AUTOSAR XML (schema 4-2-1)
package /ComponentTypes
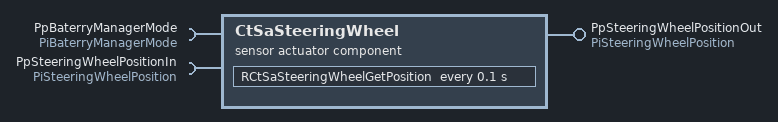
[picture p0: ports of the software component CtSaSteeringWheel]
  sensor actuator sw component type CtSaSteeringWheel
    provide port PpSteeringWheelPositionOut: nonqueued-sender-com-spec{data-element=DeSteeringWheelPosition, init-value=0}, provided-interface=PiSteeringWheelPosition
    require port PpBaterryManagerMode: mode-switch-receiver-com-spec{enhanced-mode-api=false, supports-asynchronous-mode-switch=false}, required-interface=PiBaterryManagerMode
    require port PpSteeringWheelPositionIn: nonqueued-receiver-com-spec{data-element=DeSteeringWheelPosition, filter=data-filter-type=ALWAYS, init-value=constant-reference=CSteeringWheelInitPosition}, required-interface=PiSteeringWheelPosition
    behavior CtSaSteeringWheel_InternalBehavior
      timing event TMT_RCtSaSteeringWheelGetPosition: disabled-mode=PpBaterryManagerMode.Mode.BATTERY_LOW, start-on-event=RCtSaSteeringWheelGetPosition, period=0.1
      runnable RCtSaSteeringWheelGetPosition
        data-receive-point-by-arguments:
          access REC_PpSteeringWheelPosition_DeSteeringWheelPosition: accessed-variable=PpSteeringWheelPositionIn.DeSteeringWheelPosition
        data-send-points:
          access SEND_PpSteeringWheelPositionOut_DeSteeringWheelPosition: accessed-variable=PpSteeringWheelPositionOut.DeSteeringWheelPosition
  swc implementation CtSaSteeringWheel_Implementation: behavior=CtSaSteeringWheel_InternalBehavior
    code-descriptors:
      code Default: artifact-descriptors=autosar-engineering-object={short-label=Default, category=SWSRC}
